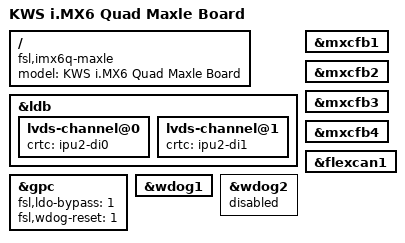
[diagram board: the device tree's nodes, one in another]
/*
 * Copyright 2012 Freescale Semiconductor, Inc.
 * Copyright 2011 Linaro Ltd.
 *
 * The code contained herein is licensed under the GNU General Public
 * License. You may obtain a copy of the GNU General Public License
 * Version 2 or later at the following locations:
 *
 * http://www.opensource.org/licenses/gpl-license.html
 * http://www.gnu.org/copyleft/gpl.html
 */

/* this file is to be included by imx6dl-maxle-XXX.dtsi  ... */

/ {
	model = "KWS i.MX6 Quad Maxle Board";
	compatible = "fsl,imx6q-maxle", "fsl,imx6q";
};

&ldb {
	lvds-channel@0 {
		crtc = "ipu2-di0";
	};

	lvds-channel@1 {
		crtc = "ipu2-di1";
	};
};

&mxcfb1 {
	status = "okay";
};


&mxcfb2 {
	status = "okay";
};

&mxcfb3 {
	status = "okay";
};

&mxcfb4 {
	status = "okay";
};

&flexcan1{
	status = "okay";
};

&gpc {
	/* use ldo-enable, u-boot will check it and configure */
	fsl,ldo-bypass = <1>;
	/* watchdog select of reset source */
	fsl,wdog-reset = <1>;
};

&wdog1 {
	status = "okay";
};

&wdog2 {
	status = "disabled";
};

